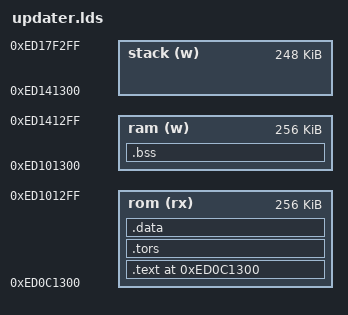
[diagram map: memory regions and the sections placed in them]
/*	updater.lds										*/
/*														*/
/* Copyright (C) 2012, Renesas Mobile Corp.				*/
/* All rights reserved.									*/
/*														*/

OUTPUT_FORMAT("elf32-littlearm", "elf32-littlearm", "elf32-littlearm")
OUTPUT_ARCH(arm)
ENTRY(_start)


MEMORY
{
    rom(rx)        : o = 0xED0C1300, l = 0x00040000
    ram(w)         : o = 0xED101300, l = 0x00040000
    stack(w)       : o = 0xED141300, l = 0x0003E000
}

SECTIONS
{
	.text 0xED0C1300 : {
		flw_boot.o(.text)
		*(.text)
		 *(.rodata)
	   	 _etext = . ;
	} > rom

	.tors : {
		__ctors = . ;
		*(.ctors)
		__ctors_end = . ;
		__dtors = . ;
		*(.dtors)
		__dtors_end = . ;
	}  > rom

	.data : AT ( ADDR(.tors) + SIZEOF(.tors) ) {
		__data = . ;
		*(.data)
		*(.tiny)
		__edata = . ;
	} > rom

	.bss : AT ( LOADADDR(.data) + SIZEOF(.data) ) {
		__bss_start = . ;
		*(.bss)
		*(COMMON)
		__bss_end = . ;
	} > ram

	__stack = 0xED141300;
}
